# MKV58F24 register map
Vendor: Freescale Semiconductor, Inc.; Series: Kinetis_V; File version: 1.6
CPU: CM7 r0p1, little endian, no MPU, FPU, VTOR, 4 interrupt priority bits
Registers are 32-bit, read-write, reset 0x0 unless marked. A register's access mark holds for its fields unless they carry their own. Offsets are from the block's base; [hi:lo] are bit positions; lines under a group give offsets from that group; {n}, {i} and the like mark numbered series; 'fields as' and 'values as' point back to an identical list.

## SystemControl — System Control Block
Base 0xE000E000; register names take the prefix SCB_
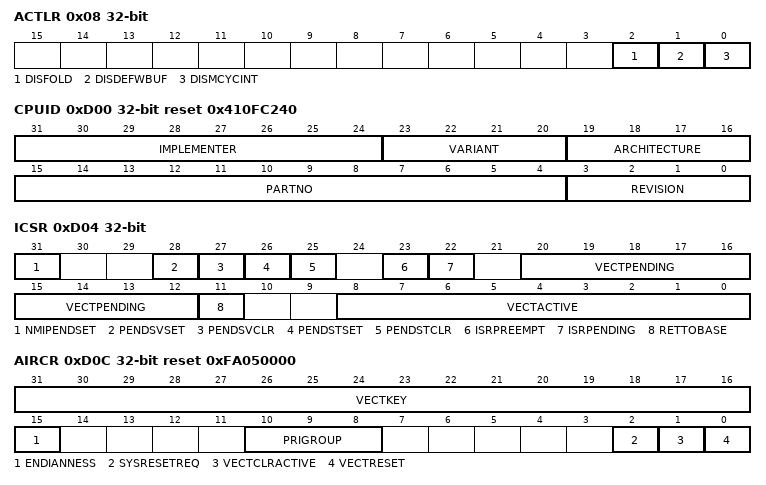
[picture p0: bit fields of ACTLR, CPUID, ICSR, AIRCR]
0x08 ACTLR — Auxiliary Control Register,
  [2] DISFOLD — Disables folding of IT instructions.
  [1] DISDEFWBUF — Disables write buffer use during default memory map accesses.
  [0] DISMCYCINT — Disables interruption of multi-cycle instructions.
0xD00 CPUID ro reset 0x410FC240 — CPUID Base Register
  [31:24] IMPLEMENTER — Implementer code
  [23:20] VARIANT — Indicates processor revision: 0x2 = Revision 2
  [19:16] ARCHITECTURE
  [15:4] PARTNO — Indicates part number
  [3:0] REVISION — Indicates patch release: 0x0 = Patch 0
0xD04 ICSR — Interrupt Control and State Register
  [31] NMIPENDSET — NMI set-pending bit
    0=write: no effect; read: NMI exception is not pending; 1=write: changes NMI exception state to pending; read: NMI exception is pending
  [28] PENDSVSET — PendSV set-pending bit
    0=write: no effect; read: PendSV exception is not pending; 1=write: changes PendSV exception state to pending; read: PendSV exception is pending
  [27] PENDSVCLR wo — PendSV clear-pending bit
    0=no effect; 1=removes the pending state from the PendSV exception
  [26] PENDSTSET — SysTick exception set-pending bit
    0=write: no effect; read: SysTick exception is not pending; 1=write: changes SysTick exception state to pending; read: SysTick exception is pending
  [25] PENDSTCLR wo — SysTick exception clear-pending bit
    0=no effect; 1=removes the pending state from the SysTick exception
  [23] ISRPREEMPT ro — Indicates whether a pending exception will be serviced on exit from debug halt state
    0=Will not service; 1=Will service a pending exception
  [22] ISRPENDING ro — Interrupt pending flag, excluding NMI and Faults
    0=No external interrupt pending; 1=External interrupt pending
  [20:12] VECTPENDING ro — Exception number of the highest priority pending enabled exception
  [11] RETTOBASE ro — Indicates whether there are preempted active exceptions
    0=there are preempted active exceptions to execute; 1=there are no active exceptions, or the currently-executing exception is the only active exception
  [8:0] VECTACTIVE ro — Active exception number
0xD08 VTOR — Vector Table Offset Register
  [31:7] TBLOFF — Vector table base offset
0xD0C AIRCR reset 0xFA050000 — Application Interrupt and Reset Control Register
  [31:16] VECTKEY — Register key
  [15] ENDIANNESS ro — Data endianness
    0=Little-endian; 1=Big-endian
  [10:8] PRIGROUP — Interrupt priority grouping field. This field determines the split of group priority from subpriority.
  [2] SYSRESETREQ wo — System reset request
    0=no system reset request; 1=asserts a signal to the outer system that requests a reset
  [1] VECTCLRACTIVE wo — Writing 1 to this bit clears all active state information for fixed and configurable exceptions.
    0=No change; 1=Clears all active state information for fixed and configurable exceptions
  [0] VECTRESET wo — Writing 1 to this bit causes a local system reset
    0=No change; 1=Causes a local system reset
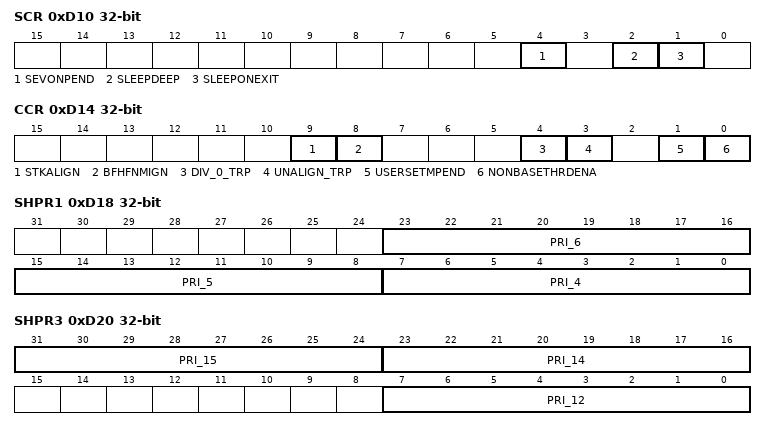
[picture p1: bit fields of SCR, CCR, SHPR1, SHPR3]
0xD10 SCR — System Control Register
  [4] SEVONPEND — Send Event on Pending bit
    0=only enabled interrupts or events can wakeup the processor, disabled interrupts are excluded; 1=enabled events and all interrupts, including disabled interrupts, can wakeup the processor
  [2] SLEEPDEEP — Controls whether the processor uses sleep or deep sleep as its low power mode
    0=sleep; 1=deep sleep
  [1] SLEEPONEXIT — Indicates sleep-on-exit when returning from Handler mode to Thread mode
    0=o not sleep when returning to Thread mode; 1=enter sleep, or deep sleep, on return from an ISR
0xD14 CCR — Configuration and Control Register
  [9] STKALIGN — Indicates stack alignment on exception entry
    0=4-byte aligned; 1=8-byte aligned
  [8] BFHFNMIGN — Enables handlers with priority -1 or -2 to ignore data BusFaults caused by load and store instructions.
    0=data bus faults caused by load and store instructions cause a lock-up; 1=handlers running at priority -1 and -2 ignore data bus faults caused by load and store instructions
  [4] DIV_0_TRP — Enables faulting or halting when the processor executes an SDIV or UDIV instruction with a divisor of 0
    0=do not trap divide by 0; 1=trap divide by 0
  [3] UNALIGN_TRP — Enables unaligned access traps
    0=do not trap unaligned halfword and word accesses; 1=trap unaligned halfword and word accesses
  [1] USERSETMPEND — Enables unprivileged software access to the STIR
    0=disable; 1=enable
  [0] NONBASETHRDENA — Indicates how the processor enters Thread mode
    0=processor can enter Thread mode only when no exception is active; 1=processor can enter Thread mode from any level under the control of an EXC_RETURN value
0xD18 SHPR1 — System Handler Priority Register 1
  [23:16] PRI_6 — Priority of system handler 6, UsageFault
  [15:8] PRI_5 — Priority of system handler 5, BusFault
  [7:0] PRI_4 — Priority of system handler 4, MemManage
0xD1C SHPR2 — System Handler Priority Register 2
  [31:24] PRI_11 — Priority of system handler 11, SVCall
0xD20 SHPR3 — System Handler Priority Register 3
  [31:24] PRI_15 — Priority of system handler 15, SysTick exception
  [23:16] PRI_14 — Priority of system handler 14, PendSV
  [7:0] PRI_12 — Priority of system handler 12, Debug Monitor
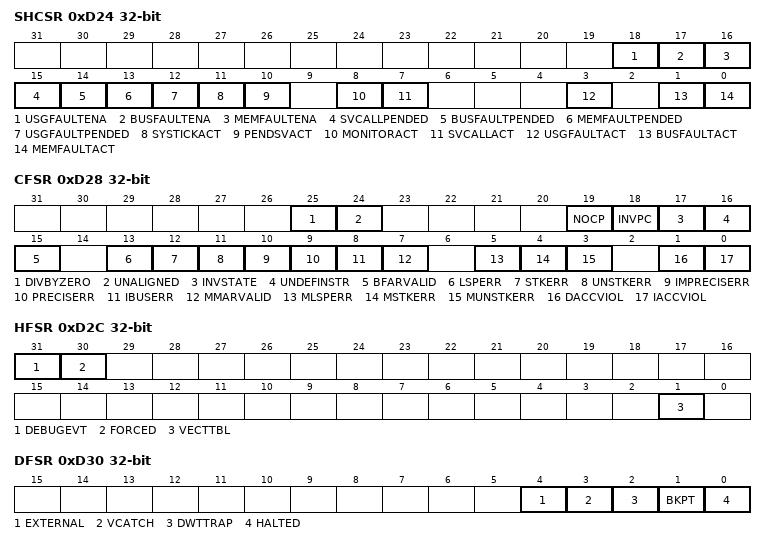
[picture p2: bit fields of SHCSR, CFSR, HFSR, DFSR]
0xD24 SHCSR — System Handler Control and State Register
  [18] USGFAULTENA — UsageFault enable bit
    0=disable the exception; 1=enable the exception
  [17] BUSFAULTENA — BusFault enable bit
    0=disable the exception; 1=enable the exception
  [16] MEMFAULTENA — MemManage enable bit
    0=disable the exception; 1=enable the exception
  [15] SVCALLPENDED — SVCall pending bit
    0=exception is not pending; 1=exception is pending
  [14] BUSFAULTPENDED — BusFault exception pending bit
    0=exception is not pending; 1=exception is pending
  [13] MEMFAULTPENDED — MemManage exception pending bit
    0=exception is not pending; 1=exception is pending
  [12] USGFAULTPENDED — UsageFault exception pending bit
    0=exception is not pending; 1=exception is pending
  [11] SYSTICKACT — SysTick exception active bit
    0=exception is not active; 1=exception is active
  [10] PENDSVACT — PendSV exception active bit
    0=exception is not active; 1=exception is active
  [8] MONITORACT — Debug monitor active bit
    0=exception is not active; 1=exception is active
  [7] SVCALLACT — SVCall active bit
    0=exception is not active; 1=exception is active
  [3] USGFAULTACT — UsageFault exception active bit
    0=exception is not active; 1=exception is active
  [1] BUSFAULTACT — BusFault exception active bit
    0=exception is not active; 1=exception is active
  [0] MEMFAULTACT — MemManage exception active bit
    0=exception is not active; 1=exception is active
0xD28 CFSR — Configurable Fault Status Register
  [25] DIVBYZERO — Divide by zero UsageFault
    0=no divide by zero fault, or divide by zero trapping not enabled; 1=the processor has executed an SDIV or UDIV instruction with a divisor of 0
  [24] UNALIGNED — Unaligned access UsageFault
    0=no unaligned access fault, or unaligned access trapping not enabled; 1=the processor has made an unaligned memory access
  [19] NOCP — No coprocessor UsageFault
    0=no UsageFault caused by attempting to access a coprocessor; 1=the processor has attempted to access a coprocessor
  [18] INVPC — Invalid PC load UsageFault, caused by an invalid PC load by EXC_RETURN
    0=no invalid PC load UsageFault; 1=the processor has attempted an illegal load of EXC_RETURN to the PC
  [17] INVSTATE — Invalid state UsageFault
    0=no invalid state UsageFault; 1=the processor has attempted to execute an instruction that makes illegal use of the EPSR
  [16] UNDEFINSTR — Undefined instruction UsageFault
    0=no undefined instruction UsageFault; 1=the processor has attempted to execute an undefined instruction
  [15] BFARVALID — BusFault Address Register (BFAR) valid flag
    0=value in BFAR is not a valid fault address; 1=BFAR holds a valid fault address
  [13] LSPERR — Bus fault occurred during floating-point lazy state preservation
    0=No bus fault occurred during floating-point lazy state preservation; 1=A bus fault occurred during floating-point lazy state preservation
  [12] STKERR — BusFault on stacking for exception entry
    0=no stacking fault; 1=stacking for an exception entry has caused one or more BusFaults
  [11] UNSTKERR — BusFault on unstacking for a return from exception
    0=no unstacking fault; 1=unstack for an exception return has caused one or more BusFaults
  [10] IMPRECISERR — Imprecise data bus error
    0=no imprecise data bus error; 1=a data bus error has occurred, but the return address in the stack frame is not related to the instruction that caused the error
  [9] PRECISERR — Precise data bus error
    0=no precise data bus error; 1=a data bus error has occurred, and the PC value stacked for the exception return points to the instruction that caused the fault
  [8] IBUSERR — Instruction bus error
    0=no instruction bus error; 1=instruction bus error
  [7] MMARVALID — MemManage Fault Address Register (MMFAR) valid flag
    0=value in MMAR is not a valid fault address; 1=MMAR holds a valid fault address
  [5] MLSPERR — MemManage fault occurred during floating-point lazy state preservation
    0=No MemManage fault occurred during floating-point lazy state preservation; 1=A MemManage fault occurred during floating-point lazy state preservation
  [4] MSTKERR — MemManage fault on stacking for exception entry
    0=no stacking fault; 1=stacking for an exception entry has caused one or more access violations
  [3] MUNSTKERR — MemManage fault on unstacking for a return from exception
    0=no unstacking fault; 1=unstack for an exception return has caused one or more access violations
  [1] DACCVIOL — Data access violation flag
    0=no data access violation fault; 1=the processor attempted a load or store at a location that does not permit the operation
  [0] IACCVIOL — Instruction access violation flag
    0=no instruction access violation fault; 1=the processor attempted an instruction fetch from a location that does not permit execution
0xD2C HFSR — HardFault Status register
  [31] DEBUGEVT — Reserved for Debug use. When writing to the register you must write 0 to this bit, otherwise behavior is Unpredictable.
    0=No Debug event has occurred; 1=Debug event has occurred. The Debug Fault Status Register has been updated.
  [30] FORCED — Indicates a forced hard fault, generated by escalation of a fault with configurable priority that cannot be handles, either because of priority or because it is disabled.
    0=no forced HardFault; 1=forced HardFault
  [1] VECTTBL — Indicates a BusFault on a vector table read during exception processing.
    0=no BusFault on vector table read; 1=BusFault on vector table read
0xD30 DFSR — Debug Fault Status Register
  [4] EXTERNAL — Debug event generated because of the assertion of an external debug request
    0=No external debug request debug event; 1=External debug request debug event
  [3] VCATCH — Indicates triggering of a Vector catch
    0=No Vector catch triggered; 1=Vector catch triggered
  [2] DWTTRAP — Debug event generated by the DWT
    0=No current debug events generated by the DWT; 1=At least one current debug event generated by the DWT
  [1] BKPT — Debug event generated by BKPT instruction execution or a breakpoint match in FPB
    0=No current breakpoint debug event; 1=At least one current breakpoint debug event
  [0] HALTED — Indicates a debug event generated by either a C_HALT or C_STEP request, triggered by a write to the DHCSR or a step request triggered by setting DEMCR.MON_STEP to 1.
    0=No active halt request debug event; 1=Halt request debug event active
0xD34 MMFAR — MemManage Fault Address Register
  [31:0] ADDRESS — Address of MemManage fault location
0xD38 BFAR — BusFault Address Register
  [31:0] ADDRESS — Address of the BusFault location
0xD3C AFSR — Auxiliary Fault Status Register
  [31:0] AUXFAULT — Latched version of the AUXFAULT inputs
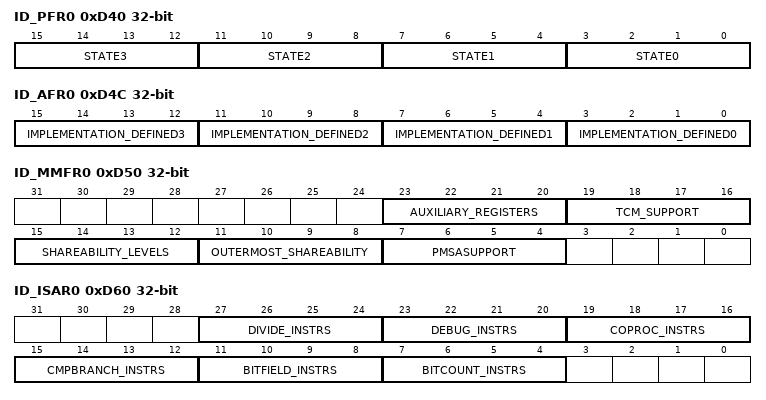
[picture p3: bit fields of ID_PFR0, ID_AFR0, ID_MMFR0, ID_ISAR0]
0xD40 ID_PFR0 ro — Processor Feature Register 0
  [15:12] STATE3 — ARMv7-M reserved
  [11:8] STATE2 — ARMv7-M reserved
  [7:4] STATE1 — Thumb instruction set support
    0=The processor does not support the ARM instruction set; 1=ARMv7-M reserved
  [3:0] STATE0 — ARM instruction set support
    0=ARMv7-M reserved; 1=ARMv7-M reserved; 2=ARMv7-M reserved; 3=Support for Thumb encoding including Thumb-2 technology, with all basic 16-bit and 32-bit instructions
0xD44 ID_PFR1 ro — Processor Feature Register 1
  [11:8] PROGMODEL — M profile programmers' model
    0=ARMv7-M reserved; 2=Two-stack programmers' model supported
0xD48 ID_DFR0 ro — Debug Feature Register
  [23:20] DEBUGMODEL — Support for memory-mapped debug model for M profile processors
    0=Not supported; 1=Support for M profile Debug architecture, with memory-mapped access
0xD4C ID_AFR0 ro — Auxiliary Feature Register
  [4n+3:4n] IMPLEMENTATION_DEFINED{n} (n=0..3) — Gives information about the IMPLEMENTATION DEFINED features of a processor implementation.
0xD50 ID_MMFR0 ro — Memory Model Feature Register 0
  [23:20] AUXILIARY_REGISTERS — Indicates the support for Auxiliary registers
    0=Not supported; 1=Support for Auxiliary Control Register only; 2=ARMv7-M reserved
  [19:16] TCM_SUPPORT — Indicates the support for Tightly Coupled Memory
    0=No tightly coupled memories implemented; 1=Tightly coupled memories implemented with IMPLEMENTATION DEFINED control; 2=ARMv7-M reserved
  [15:12] SHAREABILITY_LEVELS — Indicates the number of shareability levels implemented
    0=One level of shareability implemented; 1=ARMv7-M reserved
  [11:8] OUTERMOST_SHAREABILITY — Indicates the outermost shareability domain implemented
    0=Implemented as Non-cacheable; {v}=ARMv7-M reserved (v=1..14); 15=Shareability ignored
  [7:4] PMSASUPPORT — Indicates support for a PMSA
    0=Not supported; 1=ARMv7-M reserved; 2=ARMv7-M reserved; 3=PMSAv7, providing support for a base region and subregions
0xD54 ID_MMFR1 ro — Memory Model Feature Register 1
  [31:0] ID_MMFR1 — Gives information about the implemented memory model and memory management support.
0xD58 ID_MMFR2 ro — Memory Model Feature Register 2
  [27:24] WFI_STALL — Indicates the support for Wait For Interrupt (WFI) stalling
    0=Not supported; 1=Support for WFI stalling
0xD5C ID_MMFR3 ro — Memory Model Feature Register 3
  [31:0] ID_MMFR3 — Gives information about the implemented memory model and memory management support.
0xD60 ID_ISAR0 ro — Instruction Set Attributes Register 0
  [27:24] DIVIDE_INSTRS — Indicates the supported Divide instructions
    0=None supported, ARMv7-M reserved; 1=Adds support for the SDIV and UDIV instructions
  [23:20] DEBUG_INSTRS — Indicates the supported Debug instructions
    0=None supported, ARMv7-M reserved; 1=Adds support for the BKPT instruction
  [19:16] COPROC_INSTRS — Indicates the supported Coprocessor instructions
    0=None supported, except for separately attributed architectures, for example the Floating-point extension; 1=Adds support for generic CDP, LDC, MCR, MRC, and STC instructions; 2=As for 1, and adds support for generic CDP2, LDC2, MCR2, MRC2, and STC2 instructions; 3=As for 2, and adds support for generic MCRR and MRRC instructions; 4=As for 3, and adds support for generic MCRR2 and MRRC2 instructions
  [15:12] CMPBRANCH_INSTRS — Indicates the supported combined Compare and Branch instructions
    0=None supported, ARMv7-M reserved; 1=Adds support for the CBNZ and CBZ instructions
  [11:8] BITFIELD_INSTRS — Indicates the supported BitField instructions
    0=None supported, ARMv7-M reserved; 1=Adds support for the BFC, BFI, SBFX, and UBFX instructions
  [7:4] BITCOUNT_INSTRS — Indicates the supported Bit Counting instructions
    0=None supported, ARMv7-M reserved; 1=Adds support for the CLZ instruction
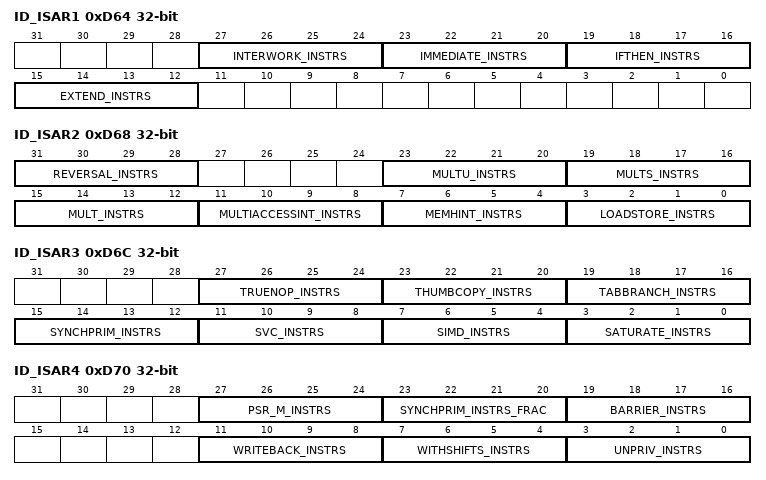
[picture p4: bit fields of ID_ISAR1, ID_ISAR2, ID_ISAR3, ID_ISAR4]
0xD64 ID_ISAR1 ro — Instruction Set Attributes Register 1
  [27:24] INTERWORK_INSTRS — Indicates the supported Interworking instructions
    0=None supported, ARMv7-M reserved; 1=Adds support for the BX instruction, and the T bit in the PSR; 2=As for 1, and adds support for the BLX instruction, and PC loads have BX-like behavior; 3=ARMv7-M reserved
  [23:20] IMMEDIATE_INSTRS — Indicates the support for data-processing instructions with long immediate
    0=None supported, ARMv7-M reserved; 1=Adds support for the ADDW, MOVW, MOVT, and SUBW instructions
  [19:16] IFTHEN_INSTRS — Indicates the supported IfThen instructions
    0=None supported, ARMv7-M reserved; 1=Adds support for the IT instructions, and for the IT bits in the PSRs
  [15:12] EXTEND_INSTRS — Indicates the supported Extend instructions
    0=None supported, ARMv7-M reserved; 1=Adds support for the SXTB, SXTH, UXTB, and UXTH instructions; 2=As for 1, and adds support for the SXTAB, SXTAB16, SXTAH, SXTB16, UXTAB, UXTAB16, UXTAH, and UXTB16 instructions
0xD68 ID_ISAR2 ro — Instruction Set Attributes Register 2
  [31:28] REVERSAL_INSTRS — Indicates the supported Reversal instructions
    0=None supported, ARMv7-M reserved; 1=Adds support for the REV, REV16, and REVSH instructions, ARMv7-M reserved; 2=As for 1, and adds support for the RBIT instruction
  [23:20] MULTU_INSTRS — Indicates the supported advanced unsigned Multiply instructions
    0=None supported, ARMv7-M reserved; 1=Adds support for the UMULL and UMLAL instructions; 2=As for 1, and adds support for the UMAAL instruction
  [19:16] MULTS_INSTRS — Indicates the supported advanced signed Multiply instructions
    0=None supported, ARMv7-M reserved; 1=Adds support for the SMULL and SMLAL instructions; 2=As for 1, and adds support for the SMLABB, SMLABT, SMLALBB, SMLALBT, SMLALTB, SMLALTT, SMLATB, SMLATT, SMLAWB, SMLAWT, SMULBB, SMULBT, SMULTB, SMULTT, SMULWB, and SMULWT instructions; 3=As for 2, and adds support for the SMLAD, SMLADX, SMLALD, SMLALDX, SMLSD, SMLSDX, SMLSLD, SMLSLDX, SMMLA, SMMLAR, SMMLS, SMMLSR, SMMUL, SMMULR, SMUAD, SMUADX, SMUSD, and SMUSDX instructions
  [15:12] MULT_INSTRS — Indicates the supported additional Multiply instructions
    0=None supported. This means only MUL is supported. ARMv7-M reserved.; 1=Adds support for the MLA instruction, ARMv7-M reserved; 2=As for 1, and adds support for the MLS instruction
  [11:8] MULTIACCESSINT_INSTRS — Indicates the support for multi-access interruptible instructions
    0=None supported. This means the LDM and STM instructions are not interruptible. ARMv7-M reserved.; 1=LDM and STM instructions are restartable; 2=LDM and STM instructions are continuable
  [7:4] MEMHINT_INSTRS — Indicates the supported Memory Hint instructions
    0=None supported, ARMv7-M reserved; 1=Adds support for the PLD instruction, ARMv7-M reserved; 2=As for 1, ARMv7-M reserved; 3=As for 1 or 2, and adds support for the PLI instruction
  [3:0] LOADSTORE_INSTRS — Indicates the supported additional load and store instructions
    0=None supported, ARMv7-M reserved; 1=Adds support for the LDRD and STRD instructions
0xD6C ID_ISAR3 ro — Instruction Set Attributes Register 3
  [27:24] TRUENOP_INSTRS — Indicates the supported non flag-setting MOV instructions
    0=None supported, ARMv7-M reserved; 1=Adds support for encoding T1 of the MOV (register) instruction copying from a low register to a low register
  [23:20] THUMBCOPY_INSTRS — Indicates the supported non flag-setting MOV instructions
    values as TRUENOP_INSTRS
  [19:16] TABBRANCH_INSTRS — Indicates the supported Table Branch instructions
    0=None supported, ARMv7-M reserved; 1=Adds support for the TBB and TBH instructions
  [15:12] SYNCHPRIM_INSTRS — Together with the ID_ISAR4[SYNCHPRIM_INSTRS_FRAC] indicates the supported Synchronization Primitives
  [11:8] SVC_INSTRS — Indicates the supported SVC instructions
    0=None supported, ARMv7-M reserved; 1=Adds support for the SVC instruction
  [7:4] SIMD_INSTRS — Indicates the supported SIMD instructions
    0=None supported, ARMv7-M reserved; 1=Adds support for the SSAT and USAT instructions, and for the Q bit in the PSRs; 3=As for 1, and adds support for the PKHBT, PKHTB, QADD16, QADD8, QASX, QSUB16, QSUB8, QSAX, SADD16, SADD8, SASX, SEL, SHADD16, SHADD8, SHASX, SHSUB16, SHSUB8, SHSAX, SSAT16, SSUB16, SSUB8, SSAX, SXTAB16, SXTB16, UADD16, UADD8, UASX, UHADD16, UHADD8, UHASX, UHSUB16, UHSUB8, UHSAX, UQADD16, UQADD8, UQASX, UQSUB16, UQSUB8, UQSAX, USAD8, USADA8, USAT16, USUB16, USUB8, USAX, UXTAB16, and UXTB16 instructions. Also adds support for the GE[3:0] bits in the PSRs.
  [3:0] SATURATE_INSTRS — Indicates the supported Saturate instructions
    0=None supported; 1=Adds support for the QADD, QDADD, QDSUB, and QSUB instructions, and for the Q bit in the PSRs
0xD70 ID_ISAR4 ro — Instruction Set Attributes Register 4
  [27:24] PSR_M_INSTRS — Indicates the supported M profile instructions to modify the PSRs
    0=None supported, ARMv7-M reserved; 1=Adds support for the M-profile forms of the CPS, MRS, and MSR instructions, to access the PSRs
  [23:20] SYNCHPRIM_INSTRS_FRAC — Together with the ID_ISAR3[SYNCHPRIM_INSTRS] indicates the supported Synchronization Primitives
  [19:16] BARRIER_INSTRS — Indicates the supported Barrier instructions
    0=None supported, ARMv7-M reserved; 1=Adds support for the DMB, DSB, and ISB barrier instructions
  [11:8] WRITEBACK_INSTRS — Indicates the support for Writeback addressing modes
    0=Basic support. Only the LDM, STM, PUSH, and POP instructions support writeback addressing modes. ARMv7-M reserved.; 1=Adds support for all of the writeback addressing modes defined in the ARMv7-M architecture
  [7:4] WITHSHIFTS_INSTRS — Indicates the support for instructions with shifts
    0=Nonzero shifts supported only in MOV and shift instructions; 1=Adds support for shifts of loads and stores over the range LSL 0-3; 3=As for 1, and adds support for other constant shift options, on loads, stores, and other instructions; 4=ARMv7-M reserved
  [3:0] UNPRIV_INSTRS — Indicates the supported unprivileged instructions. These are the instruction variants indicated by a T suffix.
    0=None supported, ARMv7-M reserved; 1=Adds support for the LDRBT, LDRT, STRBT, and STRT instructions; 2=As for 1, and adds support for the LDRHT, LDRSBT, LDRSHT, and STRHT instructions
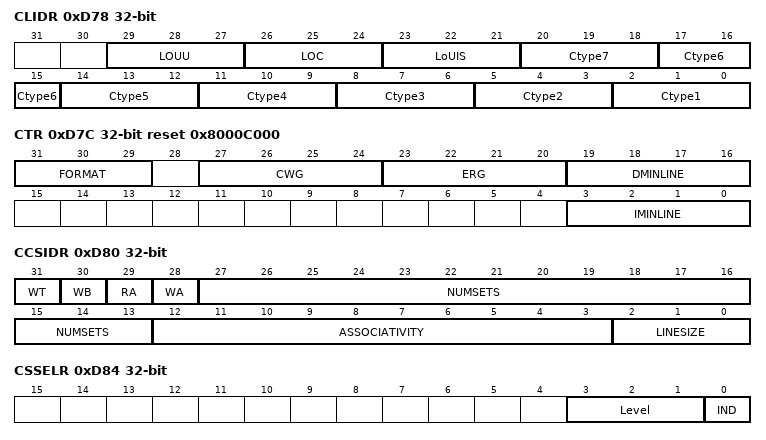
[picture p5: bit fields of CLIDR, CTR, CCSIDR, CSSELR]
0xD78 CLIDR ro — Cache Level ID register
  [29:27] LOUU — Level of Unification Uniprocessor for the cache hierarchy
    {v}={v} (v=0..7)
  [26:24] LOC — Level of Coherency for the cache hierarchy
    {v}={v} (v=0..7)
  [23:21] LoUIS — Level of Unification Inner Shareable for the cache hierarchy. This field is RAZ.
    {v}={v} (v=0..7)
  [3n-1:3n-3] Ctype{n} (n=1..7) — Indicate the type of cache implemented at level {n}.
    0=No cache; 1=Instruction cache only; 2=Data cache only; 3=Separate instruction and data caches; 4=Unified cache
0xD7C CTR ro reset 0x8000C000 — Cache Type register
  [31:29] FORMAT — Indicates the implemented CTR format.
    4=ARMv7 format
  [27:24] CWG — Cache Write-back Granule. The maximum size of memory that can be overwritten as a result of the eviction of a cache entry that has had a memory location in it modified, encoded as Log2 of the number of words.
  [23:20] ERG — Exclusives Reservation Granule. The maximum size of the reservation granule that has been implemented for the Load-Exclusive and Store-Exclusive instructions, encoded as Log2 of the number of words.
  [19:16] DMINLINE — Log2 of the number of words in the smallest cache line of all the data caches and unified caches that are controlled by the processor.
  [3:0] IMINLINE — Log2 of the number of words in the smallest cache line of all the instruction caches that are controlled by the processor.
0xD80 CCSIDR ro — Cache Size ID Register
  [31] WT — Indicates whether the cache level supports write-through
    0=Feature not supported; 1=Feature supported
  [30] WB — Indicates whether the cache level supports write-back
    0=Feature not supported; 1=Feature supported
  [29] RA — Indicates whether the cache level supports read-allocation
    0=Feature not supported; 1=Feature supported
  [28] WA — Indicates whether the cache level supports write-allocation
    0=Feature not supported; 1=Feature supported
  [27:13] NUMSETS — (Number of sets in cache) - 1, therefore a value of 0 indicates 1 set in the cache. The number of sets does not have to be a power of 2.
  [12:3] ASSOCIATIVITY — (Associativity of cache) - 1, therefore a value of 0 indicates an associativity of 1. The associativity does not have to be a power of 2.
  [2:0] LINESIZE — (Log2(Number of words in cache line)) - 2.
    0=The line length of 4 words; 1=The line length of 8 words; 2=The line length of 16 words; 3=The line length of 32 words; 4=The line length of 64 words; 5=The line length of 128 words; 6=The line length of 256 words; 7=The line length of 512 words
0xD84 CSSELR — Cache Size Selection Register
  [3:1] Level — Cache level of required cache
    {v}=Level {v+1} cache (v=0..6)
  [0] IND — Instruction not data bit
    0=Data or unified cache; 1=Instruction cache
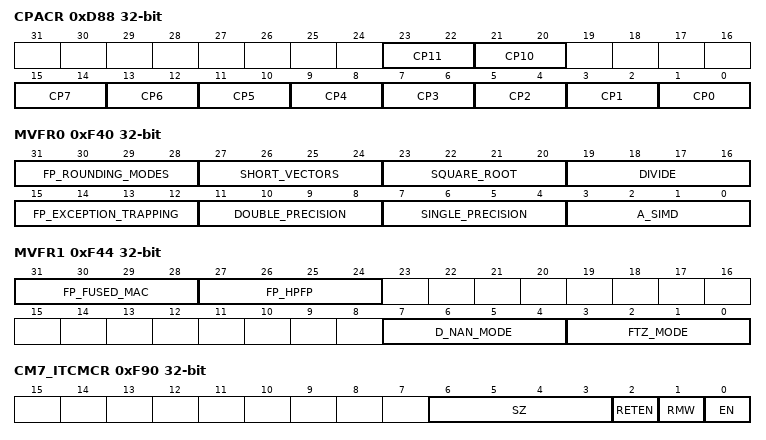
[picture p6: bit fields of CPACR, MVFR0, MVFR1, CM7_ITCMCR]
0xD88 CPACR — Coprocessor Access Control Register
  [all] fields
    0=Access denied. Any attempted access generates a NOCP UsageFault.; 1=Privileged access only. An unprivileged access generates a NOCP UsageFault.; 2=Reserved. The result of any access is UNPREDICTABLE.; 3=Full access
  [23:22] CP11 — Access privileges for coprocessor 11.
  [21:20] CP10 — Access privileges for coprocessor 10.
  [2n+1:2n] CP{n} (n=0..7) — Access privileges for coprocessor {n}.
0xF00 STIR wo — Software Triggered Interrupt Register
  [8:0] INTID — Indicates the interrupt to be triggered
0xF40 MVFR0 ro — Media and FP Feature Register 0
  [31:28] FP_ROUNDING_MODES — Indicates the rounding modes supported by the FP floating-point hardware.
    1=All rounding modes supported
  [27:24] SHORT_VECTORS — Indicates the hardware support for FP square root operations.
    0=Not supported in ARMv7-M
  [23:20] SQUARE_ROOT — Indicates the hardware support for FP square root operations.
    1=Supported
  [19:16] DIVIDE — Indicates whether the FP hardware implementation supports exception trapping.
    1=Supported
  [15:12] FP_EXCEPTION_TRAPPING — Indicates whether the FP hardware implementation supports exception trapping.
    0=Not supported in ARMv7-M
  [11:8] DOUBLE_PRECISION — Indicates the hardware support for FP double-precision operations.
    0=Not supported; 2=Supported
  [7:4] SINGLE_PRECISION — Indicates the hardware support for FP single-precision operations.
    0=Not supported; 2=Supported
  [3:0] A_SIMD — Indicates the size of the FP register bank.
    1=Supported, 16 x 64-bit registers
0xF44 MVFR1 ro — Media and FP Feature Register 1
  [31:28] FP_FUSED_MAC — Indicates whether the FP supports fused multiply accumulate operations.
    1=Supported
  [27:24] FP_HPFP — Floating Point Half-Precision and double-precision.
    1=Supports conversion between half-precision and single precision; 2=As for 0b0001, and also supports conversion between half-precision and double-precision
  [7:4] D_NAN_MODE — Indicates whether the FP hardware implementation supports only the Default NaN mode.
    1=Hardware supports propagation of NaN values
  [3:0] FTZ_MODE — Indicates whether the FP hardware implementation supports only the Flush-to-Zero mode of operation.
    1=Hardware supports full denormalized number arithmetic
0xF48 MVFR2 ro — Media and FP Feature Register 2
  [7:4] VFP_MISC — Indicates the hardware support for FP miscellaneous features.
    0=No support for miscellaneous features; 4=Support for floating-point selection, floating-point conversion to integer with direct rounding modes, floating-point round to integral floating-point, and floating-point maximum number and minimum number
0xF50 ICIALLU wo — Instruction cache invalidate all to Point of Unification (PoU)
  [31:0] ICIALLU — I-cache invalidate all to PoU
0xF58 ICIMVAU wo — Instruction cache invalidate by address to PoU
  [31:0] ICIMVAU — I-cache invalidate by MVA to PoU
0xF5C DCIMVAC wo — Data cache invalidate by address to Point of Coherency (PoC)
  [31:0] DCIMVAC — D-cache invalidate by MVA to PoC
0xF60 DCISW wo — Data cache invalidate by set/way
  [31:0] DCISW — D-cache invalidate by set-way
0xF64 DCCMVAU wo — Data cache by address to PoU
  [31:0] DCCMVAU — D-cache clean by MVA to PoU
0xF68 DCCMVAC wo — Data cache clean by address to PoC
  [31:0] DCCMVAC — D-cache clean by MVA to PoC
0xF6C DCCSW wo — Data cache clean by set/way
  [31:0] DCCSW — D-cache clean by set-way
0xF70 DCCIMVAC wo — Data cache clean and invalidate by address to PoC
  [31:0] DCCIMVAC — D-cache clean and invalidate by MVA to PoC
0xF74 DCCISW wo — Data cache clean and invalidate by set/way
  [31:0] DCCISW — D-cache clean and invalidate by set-way
0xF90 CM7_ITCMCR — Instruction Tightly-Coupled Memory Control Register
  [6:3] SZ ro — TCM size. Indicates the size of the relevant TCM.
    0=No TCM implemented; 3=4KB; 4=8KB; 5=16KB; 6=32KB; 7=64KB; 8=128KB; 9=256KB; 10=512KB; 11=1MB; 12=2MB; 13=4MB; 14=8MB; 15=16MB
  [2] RETEN — Retry phase enable. When enabled the processor guarantees to honor the retry output on the corresponding TCM interface, re-executing the instruction which carried out the TCM access.
    0=Retry phase disabled; 1=Retry phase enabled
  [1] RMW — Read-Modify-Write (RMW) enable. Indicates that all writes to TCM, that are not the full width of the TCM RAM, use a RMW sequence.
    0=RMW disabled; 1=RMW enabled
  [0] EN — TCM enable. When a TCM is disabled all accesses are made to the AXIM interface.
    0=TCM disabled; 1=TCM enabled
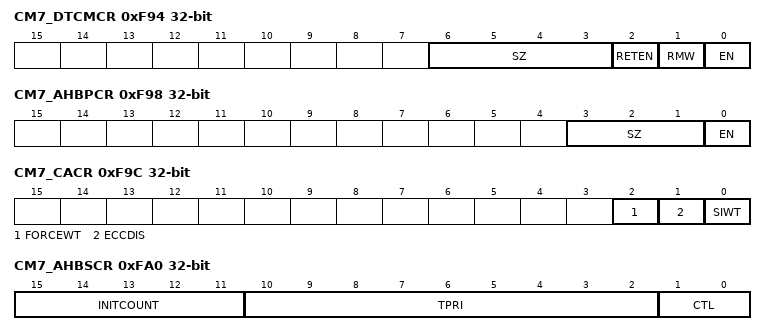
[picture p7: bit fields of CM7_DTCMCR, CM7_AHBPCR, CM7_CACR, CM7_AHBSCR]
0xF94 CM7_DTCMCR — Data Tightly-Coupled Memory Control Register
  fields as CM7_ITCMCR
0xF98 CM7_AHBPCR — AHBP Control Register
  [3:1] SZ ro — AHBP size.
    0=0MB. AHBP disabled.; 1=64MB; 2=128MB; 3=256MB; 4=512MB
  [0] EN — AHBP enable.
    0=AHBP disabled. When disabled all accesses are made to the AXIM interface.; 1=AHBP enabled
0xF9C CM7_CACR — L1 Cache Control Register
  [2] FORCEWT — Enables Force Write-Through in the data cache.
    0=Disables Force Write-Through; 1=Enables Force Write-Through. All Cacheable memory regions are treated as Write-Through.
  [1] ECCDIS — Enables ECC in the instruction and data cache.
    0=Enables ECC in the instruction and data cache; 1=Disables ECC in the instruction and data cache
  [0] SIWT — Shared cacheable-is-WT for data cache. Enables limited cache coherency usage.
    0=Normal Cacheable Shared locations are treated as being Non-cacheable. Default mode of operation for Shared memory.; 1=Normal Cacheable shared locations are treated as Write-Through
0xFA0 CM7_AHBSCR — AHB Slave Control Register
  [15:11] INITCOUNT — Fairness counter initialization value.
  [10:2] TPRI — Threshold execution priority for AHBS traffic demotion.
  [1:0] CTL — AHBS prioritization control.
    0=AHBS access priority demoted. This is the reset value.; 1=Software access priority demoted; 2=AHBS access priority demoted by initializing the fairness counter to the CM7_AHBSCR[INITCOUNT] value when the software execution priority is higher than or equal to the threshold level programed in CM7_AHBSCR[TPRI]; 3=AHBSPRI signal has control of access priority
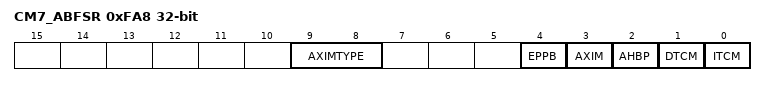
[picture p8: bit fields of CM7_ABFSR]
0xFA8 CM7_ABFSR — Auxiliary Bus Fault Status Register
  [9:8] AXIMTYPE — Indicates the type of fault on the AXIM interface. Only valid when AXIM is 1.
    0=OKAY; 1=EXOKAY; 2=SLVERR; 3=DECERR
  [4] EPPB — Asynchronous fault on EPPB interface.
  [3] AXIM — Asynchronous fault on AXIM interface.
  [2] AHBP — Asynchronous fault on AHBP interface.
  [1] DTCM — Asynchronous fault on DTCM interface.
  [0] ITCM — Asynchronous fault on ITCM interface.
